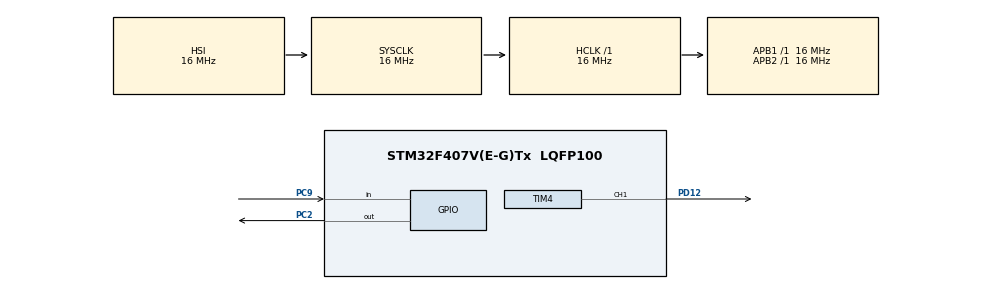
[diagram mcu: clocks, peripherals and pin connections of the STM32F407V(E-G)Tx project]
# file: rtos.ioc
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FREERTOS.Tasks01=defaultTask,0,128,StartDefaultTask,Default,NULL,Dynamic,NULL,NULL;myTask02,-3,128,StartTask02,Default,NULL,Dynamic,NULL,NULL
Mcu.Family=STM32F4
Mcu.Name=STM32F407V(E-G)Tx
Mcu.Package=LQFP100
NVIC.PriorityGroup=NVIC_PRIORITYGROUP_4
PC2.Signal=GPIO_Output
PC9.Signal=GPIO_Input
PD12.Signal=S_TIM4_CH1
ProjectManager.HeapSize=0x200
ProjectManager.StackSize=0x400
ProjectManager.TargetToolchain=STM32CubeIDE
RCC.AHBFreq_Value=16000000
RCC.APB1Freq_Value=16000000
RCC.APB2Freq_Value=16000000
RCC.CortexFreq_Value=16000000
RCC.HSE_VALUE=25000000
RCC.HSI_VALUE=16000000
RCC.LSE_VALUE=32768
RCC.SYSCLKFreq_VALUE=16000000
RCC.VCOOutputFreq_Value=192000000
SH.S_TIM4_CH1.0=TIM4_CH1,PWM Generation1 CH1
TIM4.Channel-PWM\ Generation1\ CH1=TIM_CHANNEL_1
TIM4.Period=220
TIM4.Prescaler=1
VP_FREERTOS_VS_CMSIS_V1.Mode=CMSIS_V1
VP_TIM4_VS_ClockSourceINT.Mode=Internal
board=custom

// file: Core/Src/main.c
/* USER CODE BEGIN Header */
/**
  ******************************************************************************
  * @file           : main.c
  * @brief          : Main program body
  ******************************************************************************
  * @attention
  *
  * Copyright (c) 2025 STMicroelectronics.
  * All rights reserved.
  *
  * This software is licensed under terms that can be found in the LICENSE file
  * in the root directory of this software component.
  * If no LICENSE file comes with this software, it is provided AS-IS.
  *
  ******************************************************************************
  */
/* USER CODE END Header */
#include "main.h"
#include "cmsis_os.h"

/* USER CODE BEGIN PM */
uint8_t status;
/* USER CODE END PM */

TIM_HandleTypeDef htim4;

osThreadId defaultTaskHandle;
osThreadId myTask02Handle;

void SystemClock_Config(void);
static void MX_GPIO_Init(void);
static void MX_TIM4_Init(void);
void StartDefaultTask(void const * argument);
void StartTask02(void const * argument);

/* USER CODE BEGIN PFP */
void const *argument;
/* USER CODE END PFP */

/* USER CODE BEGIN 0 */
void func1(void){
	HAL_Delay(1000);
	HAL_GPIO_WritePin(GPIOC, GPIO_PIN_2, GPIO_PIN_RESET);
	StartTask02(&argument);

}
/* USER CODE END 0 */

int main(void)
{

  /* MCU Configuration--------------------------------------------------------*/

  /* Reset of all peripherals, Initializes the Flash interface and the Systick. */
  HAL_Init();

  /* Configure the system clock */
  SystemClock_Config();

  /* Initialize all configured peripherals */
  MX_GPIO_Init();
  MX_TIM4_Init();
  /* USER CODE BEGIN 2 */
  HAL_TIM_PWM_Start(&htim4, TIM_CHANNEL_1);
  /* USER CODE END 2 */

  /* Create the thread(s) */
  /* definition and creation of defaultTask */
  osThreadDef(defaultTask, StartDefaultTask, osPriorityNormal, 0, 128);
  defaultTaskHandle = osThreadCreate(osThread(defaultTask), NULL);

  /* definition and creation of myTask02 */
  osThreadDef(myTask02, StartTask02, osPriorityIdle, 0, 128);
  myTask02Handle = osThreadCreate(osThread(myTask02), NULL);

  /* Start scheduler */
  osKernelStart();

  /* We should never get here as control is now taken by the scheduler */

  /* Infinite loop */
  while (1)
  {

  }
}

void SystemClock_Config(void)
{
  RCC_OscInitTypeDef RCC_OscInitStruct = {0};
  RCC_ClkInitTypeDef RCC_ClkInitStruct = {0};

  /** Configure the main internal regulator output voltage
  */
  __HAL_RCC_PWR_CLK_ENABLE();
  __HAL_PWR_VOLTAGESCALING_CONFIG(PWR_REGULATOR_VOLTAGE_SCALE1);

  /** Initializes the RCC Oscillators according to the specified parameters
  * in the RCC_OscInitTypeDef structure.
  */
  RCC_OscInitStruct.OscillatorType = RCC_OSCILLATORTYPE_HSI;
  RCC_OscInitStruct.HSIState = RCC_HSI_ON;
  RCC_OscInitStruct.HSICalibrationValue = RCC_HSICALIBRATION_DEFAULT;
  RCC_OscInitStruct.PLL.PLLState = RCC_PLL_NONE;
  if (HAL_RCC_OscConfig(&RCC_OscInitStruct) != HAL_OK)
  {
    Error_Handler();
  }

  /** Initializes the CPU, AHB and APB buses clocks
  */
  RCC_ClkInitStruct.ClockType = RCC_CLOCKTYPE_HCLK|RCC_CLOCKTYPE_SYSCLK
                              |RCC_CLOCKTYPE_PCLK1|RCC_CLOCKTYPE_PCLK2;
  RCC_ClkInitStruct.SYSCLKSource = RCC_SYSCLKSOURCE_HSI;
  RCC_ClkInitStruct.AHBCLKDivider = RCC_SYSCLK_DIV1;
  RCC_ClkInitStruct.APB1CLKDivider = RCC_HCLK_DIV1;
  RCC_ClkInitStruct.APB2CLKDivider = RCC_HCLK_DIV1;

  if (HAL_RCC_ClockConfig(&RCC_ClkInitStruct, FLASH_LATENCY_0) != HAL_OK)
  {
    Error_Handler();
  }
}

static void MX_TIM4_Init(void)
{

  TIM_ClockConfigTypeDef sClockSourceConfig = {0};
  TIM_MasterConfigTypeDef sMasterConfig = {0};
  TIM_OC_InitTypeDef sConfigOC = {0};

  htim4.Instance = TIM4;
  htim4.Init.Prescaler = 1;
  htim4.Init.CounterMode = TIM_COUNTERMODE_UP;
  htim4.Init.Period = 220;
  htim4.Init.ClockDivision = TIM_CLOCKDIVISION_DIV1;
  htim4.Init.AutoReloadPreload = TIM_AUTORELOAD_PRELOAD_DISABLE;
  if (HAL_TIM_Base_Init(&htim4) != HAL_OK)
  {
    Error_Handler();
  }
  sClockSourceConfig.ClockSource = TIM_CLOCKSOURCE_INTERNAL;
  if (HAL_TIM_ConfigClockSource(&htim4, &sClockSourceConfig) != HAL_OK)
  {
    Error_Handler();
  }
  if (HAL_TIM_PWM_Init(&htim4) != HAL_OK)
  {
    Error_Handler();
  }
  sMasterConfig.MasterOutputTrigger = TIM_TRGO_RESET;
  sMasterConfig.MasterSlaveMode = TIM_MASTERSLAVEMODE_DISABLE;
  if (HAL_TIMEx_MasterConfigSynchronization(&htim4, &sMasterConfig) != HAL_OK)
  {
    Error_Handler();
  }
  sConfigOC.OCMode = TIM_OCMODE_PWM1;
  sConfigOC.Pulse = 0;
  sConfigOC.OCPolarity = TIM_OCPOLARITY_HIGH;
  sConfigOC.OCFastMode = TIM_OCFAST_DISABLE;
  if (HAL_TIM_PWM_ConfigChannel(&htim4, &sConfigOC, TIM_CHANNEL_1) != HAL_OK)
  {
    Error_Handler();
  }
  HAL_TIM_MspPostInit(&htim4);

}

static void MX_GPIO_Init(void)
{
  GPIO_InitTypeDef GPIO_InitStruct = {0};

  /* GPIO Ports Clock Enable */
  __HAL_RCC_GPIOC_CLK_ENABLE();
  __HAL_RCC_GPIOD_CLK_ENABLE();

  /*Configure GPIO pin Output Level */
  HAL_GPIO_WritePin(GPIOC, GPIO_PIN_2, GPIO_PIN_RESET);

  /*Configure GPIO pin : PC2 */
  GPIO_InitStruct.Pin = GPIO_PIN_2;
  GPIO_InitStruct.Mode = GPIO_MODE_OUTPUT_PP;
  GPIO_InitStruct.Pull = GPIO_NOPULL;
  GPIO_InitStruct.Speed = GPIO_SPEED_FREQ_LOW;
  HAL_GPIO_Init(GPIOC, &GPIO_InitStruct);

  /*Configure GPIO pin : PC9 */
  GPIO_InitStruct.Pin = GPIO_PIN_9;
  GPIO_InitStruct.Mode = GPIO_MODE_INPUT;
  GPIO_InitStruct.Pull = GPIO_NOPULL;
  HAL_GPIO_Init(GPIOC, &GPIO_InitStruct);

}

void StartDefaultTask(void const * argument)
{
  /* USER CODE BEGIN 5 */
  /* Infinite loop */
  for(;;)
  {
	  HAL_GPIO_WritePin(GPIOC, GPIO_PIN_2, GPIO_PIN_SET);
	  func1();
    osDelay(1);
  }
  /* USER CODE END 5 */
}

void StartTask02(void const * argument)
{
  /* USER CODE BEGIN StartTask02 */
  /* Infinite loop */
  for(;;)
  {
	  __HAL_TIM_SET_COMPARE(&htim4, TIM_CHANNEL_1, 500);
	  osDelay(500);
	  __HAL_TIM_SET_COMPARE(&htim4, TIM_CHANNEL_1, 0);
	  osDelay(500);

    osDelay(1);
  }
  /* USER CODE END StartTask02 */
}

void Error_Handler(void)
{
  __disable_irq();
  while (1)
  {
  }
}
